# fpu register map
Vendor: Texas Instruments
Peripheral module from a debugger description file (folder MSP432).
Registers are 32-bit, read-write, no defined reset value unless marked. A register's access mark holds for its fields unless they carry their own. Offsets are as the file gives them; lines under a group give offsets from that group; [hi:lo] are bit positions; {n}, {i} and the like mark numbered series; 'fields as' and 'values as' point back to an identical list; <NAME> marks a mode.

## FPU
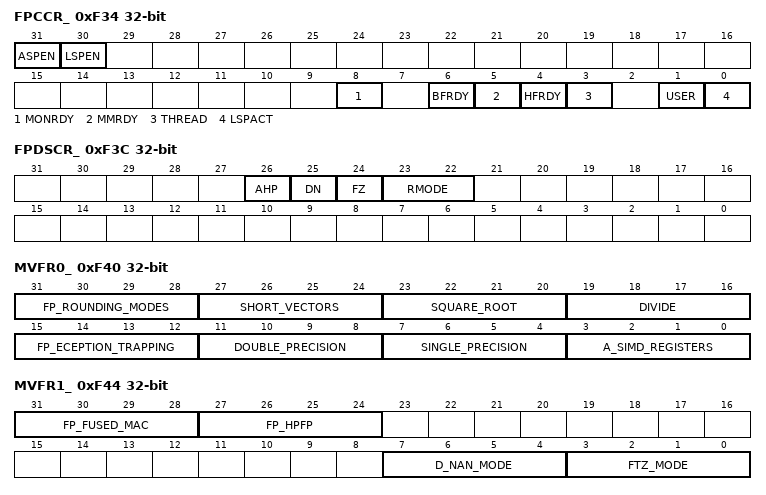
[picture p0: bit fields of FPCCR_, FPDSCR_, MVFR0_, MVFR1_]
0xF34 FPCCR_ — Floating Point Context Control Register
  [31] ASPEN — Automatic State Preservation ENable
  [30] LSPEN — Lazy State Preservation ENable
  [8] MONRDY — Indicates whether the the software executing when the processor
  [6] BFRDY — Indicates whether the software executing when the processor all
  [5] MMRDY — Indicates whether the software executing when the processor all
  [4] HFRDY — Indicates whether the software executing when the processor all
  [3] THREAD — Indicates the processor mode was Thread when it allocated the F
  [1] USER — Indicates the privilege level of the software executing was Use
  [0] LSPACT — Indicates whether Lazy preservation of the FP state is active.
0xF38 FPCAR_ — Floating-Point Context Address Register
  [30:2] ADDRESS — Holds the (double-word-aligned) location of the unpopulated flo
0xF3C FPDSCR_ — Floating Point Default Status Control Register
  [26] AHP — Default value for Alternative Half Precision bit
  [25] DN — Default value for Default NaN mode bit
  [24] FZ — Default value for Flush-to-Zero mode bit
  [23:22] RMODE — Default value for Rounding Mode control field
0xF40 MVFR0_ — Media and FP Feature Register 0 (MVFR0)
  [31:28] FP_ROUNDING_MODES — Indicates the rounding modes supported by the FP floating-point
  [27:24] SHORT_VECTORS — Indicates the hardware support for FP short vectors
  [23:20] SQUARE_ROOT — Indicates the hardware support for FP square root operations
  [19:16] DIVIDE — Indicates the hardware support for FP divide operations
  [15:12] FP_ECEPTION_TRAPPING — Indicates whether the FP hardware implementation supports excep
  [11:8] DOUBLE_PRECISION — Indicates the hardware support for FP double-precision operatio
  [7:4] SINGLE_PRECISION — Indicates the hardware support for FP single-precision operatio
  [3:0] A_SIMD_REGISTERS — Indicates the size of the FP register bank
0xF44 MVFR1_ — Media and FP Feature Register 1 (MVFR1)
  [31:28] FP_FUSED_MAC — Indicates whether the FP supports fused multiply accumulate ope
  [27:24] FP_HPFP — Indicates whether the FP supports half-precision floating-point
  [7:4] D_NAN_MODE — Indicates whether the FP hardware implementation supports only
  [3:0] FTZ_MODE — Indicates whether the FP hardware implementation supports only
